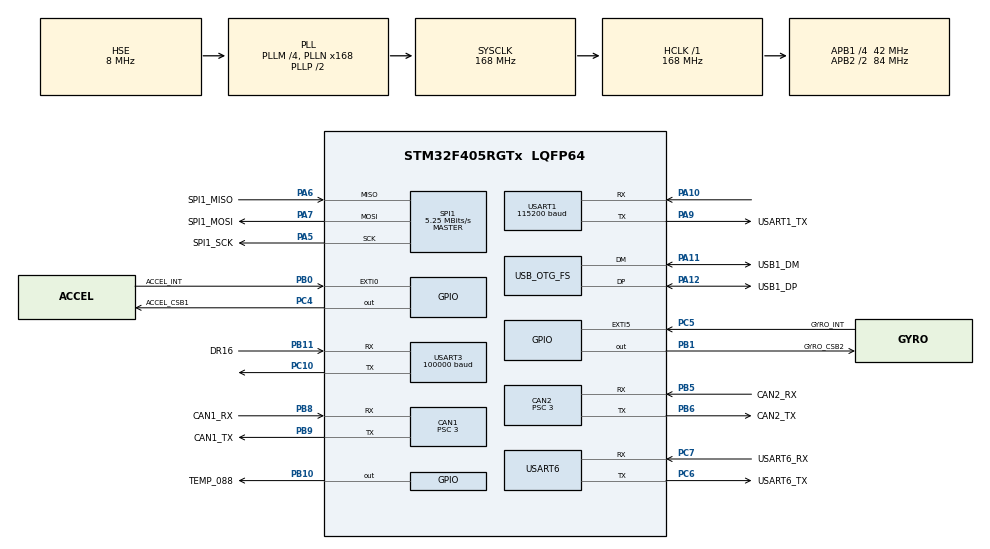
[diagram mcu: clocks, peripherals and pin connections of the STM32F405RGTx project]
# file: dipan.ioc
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CAN1.ABOM=ENABLE
CAN1.AWUM=ENABLE
CAN1.BS1=CAN_BS1_10TQ
CAN1.BS2=CAN_BS2_3TQ
CAN1.CalculateBaudRate=1000000
CAN1.CalculateTimeBit=1000
CAN1.CalculateTimeQuantum=71.42857142857143
CAN1.NART=ENABLE
CAN1.Prescaler=3
CAN2.ABOM=ENABLE
CAN2.AWUM=ENABLE
CAN2.BS1=CAN_BS1_10TQ
CAN2.BS2=CAN_BS2_3TQ
CAN2.CalculateBaudRate=1000000
CAN2.CalculateTimeBit=1000
CAN2.CalculateTimeQuantum=71.42857142857143
CAN2.NART=ENABLE
CAN2.Prescaler=3
Dma.Request0=SPI1_RX
Dma.Request1=SPI1_TX
Dma.Request2=USART1_RX
Dma.Request3=USART1_TX
Dma.Request4=USART6_RX
Dma.Request5=USART6_TX
Dma.Request6=USART3_RX
Dma.SPI1_RX.0.Direction=DMA_PERIPH_TO_MEMORY
Dma.SPI1_RX.0.FIFOMode=DMA_FIFOMODE_DISABLE
Dma.SPI1_RX.0.Instance=DMA2_Stream0
Dma.SPI1_RX.0.MemDataAlignment=DMA_MDATAALIGN_BYTE
Dma.SPI1_RX.0.MemInc=DMA_MINC_ENABLE
Dma.SPI1_RX.0.Mode=DMA_NORMAL
Dma.SPI1_RX.0.PeriphDataAlignment=DMA_PDATAALIGN_BYTE
Dma.SPI1_RX.0.PeriphInc=DMA_PINC_DISABLE
Dma.SPI1_RX.0.Priority=DMA_PRIORITY_LOW
Dma.SPI1_TX.1.Direction=DMA_MEMORY_TO_PERIPH
Dma.SPI1_TX.1.FIFOMode=DMA_FIFOMODE_DISABLE
Dma.SPI1_TX.1.Instance=DMA2_Stream3
Dma.SPI1_TX.1.MemDataAlignment=DMA_MDATAALIGN_BYTE
Dma.SPI1_TX.1.MemInc=DMA_MINC_ENABLE
Dma.SPI1_TX.1.Mode=DMA_NORMAL
Dma.SPI1_TX.1.PeriphDataAlignment=DMA_PDATAALIGN_BYTE
Dma.SPI1_TX.1.PeriphInc=DMA_PINC_DISABLE
Dma.SPI1_TX.1.Priority=DMA_PRIORITY_LOW
Dma.USART1_RX.2.Direction=DMA_PERIPH_TO_MEMORY
Dma.USART1_RX.2.FIFOMode=DMA_FIFOMODE_DISABLE
Dma.USART1_RX.2.Instance=DMA2_Stream2
Dma.USART1_RX.2.MemDataAlignment=DMA_MDATAALIGN_BYTE
Dma.USART1_RX.2.MemInc=DMA_MINC_ENABLE
Dma.USART1_RX.2.Mode=DMA_NORMAL
Dma.USART1_RX.2.PeriphDataAlignment=DMA_PDATAALIGN_BYTE
Dma.USART1_RX.2.PeriphInc=DMA_PINC_DISABLE
Dma.USART1_RX.2.Priority=DMA_PRIORITY_LOW
Dma.USART1_TX.3.Direction=DMA_MEMORY_TO_PERIPH
Dma.USART1_TX.3.FIFOMode=DMA_FIFOMODE_DISABLE
Dma.USART1_TX.3.Instance=DMA2_Stream7
Dma.USART1_TX.3.MemDataAlignment=DMA_MDATAALIGN_BYTE
Dma.USART1_TX.3.MemInc=DMA_MINC_ENABLE
Dma.USART1_TX.3.Mode=DMA_NORMAL
Dma.USART1_TX.3.PeriphDataAlignment=DMA_PDATAALIGN_BYTE
Dma.USART1_TX.3.PeriphInc=DMA_PINC_DISABLE
Dma.USART1_TX.3.Priority=DMA_PRIORITY_LOW
Dma.USART3_RX.6.Direction=DMA_PERIPH_TO_MEMORY
Dma.USART3_RX.6.FIFOMode=DMA_FIFOMODE_DISABLE
Dma.USART3_RX.6.Instance=DMA1_Stream1
Dma.USART3_RX.6.MemDataAlignment=DMA_MDATAALIGN_BYTE
Dma.USART3_RX.6.MemInc=DMA_MINC_ENABLE
Dma.USART3_RX.6.Mode=DMA_NORMAL
Dma.USART3_RX.6.PeriphDataAlignment=DMA_PDATAALIGN_BYTE
Dma.USART3_RX.6.PeriphInc=DMA_PINC_DISABLE
Dma.USART3_RX.6.Priority=DMA_PRIORITY_LOW
Dma.USART6_RX.4.Direction=DMA_PERIPH_TO_MEMORY
Dma.USART6_RX.4.FIFOMode=DMA_FIFOMODE_DISABLE
Dma.USART6_RX.4.Instance=DMA2_Stream1
Dma.USART6_RX.4.MemDataAlignment=DMA_MDATAALIGN_BYTE
Dma.USART6_RX.4.MemInc=DMA_MINC_ENABLE
Dma.USART6_RX.4.Mode=DMA_NORMAL
Dma.USART6_RX.4.PeriphDataAlignment=DMA_PDATAALIGN_BYTE
Dma.USART6_RX.4.PeriphInc=DMA_PINC_DISABLE
Dma.USART6_RX.4.Priority=DMA_PRIORITY_LOW
Dma.USART6_TX.5.Direction=DMA_MEMORY_TO_PERIPH
Dma.USART6_TX.5.FIFOMode=DMA_FIFOMODE_DISABLE
Dma.USART6_TX.5.Instance=DMA2_Stream6
Dma.USART6_TX.5.MemDataAlignment=DMA_MDATAALIGN_BYTE
Dma.USART6_TX.5.MemInc=DMA_MINC_ENABLE
Dma.USART6_TX.5.Mode=DMA_NORMAL
Dma.USART6_TX.5.PeriphDataAlignment=DMA_PDATAALIGN_BYTE
Dma.USART6_TX.5.PeriphInc=DMA_PINC_DISABLE
Dma.USART6_TX.5.Priority=DMA_PRIORITY_LOW
FREERTOS.Tasks01=defaultTask,24,128,StartDefaultTask,Default,NULL,Dynamic,NULL,NULL
FREERTOS.configTOTAL_HEAP_SIZE=30000
Mcu.Family=STM32F4
Mcu.Name=STM32F405RGTx
Mcu.Package=LQFP64
NVIC.CAN1_RX0_IRQn=true\:5\:0\:false\:false\:true\:true\:true\:true\:true
NVIC.CAN2_RX0_IRQn=true\:5\:0\:false\:false\:true\:true\:true\:true\:true
NVIC.DMA1_Stream1_IRQn=true\:5\:0\:false\:false\:true\:true\:false\:true\:true
NVIC.DMA2_Stream0_IRQn=true\:5\:0\:false\:false\:true\:true\:false\:true\:true
NVIC.DMA2_Stream1_IRQn=true\:5\:0\:false\:false\:true\:true\:false\:true\:true
NVIC.DMA2_Stream2_IRQn=true\:5\:0\:false\:false\:true\:true\:false\:true\:true
NVIC.DMA2_Stream3_IRQn=true\:5\:0\:false\:false\:true\:true\:false\:true\:true
NVIC.DMA2_Stream6_IRQn=true\:5\:0\:false\:false\:true\:true\:false\:true\:true
NVIC.DMA2_Stream7_IRQn=true\:5\:0\:false\:false\:true\:true\:false\:true\:true
NVIC.OTG_FS_IRQn=true\:5\:0\:false\:false\:true\:true\:false\:true\:true
NVIC.PriorityGroup=NVIC_PRIORITYGROUP_4
NVIC.TIM8_TRG_COM_TIM14_IRQn=true\:15\:0\:false\:false\:true\:false\:false\:true\:true
NVIC.TimeBase=TIM8_TRG_COM_TIM14_IRQn
NVIC.TimeBaseIP=TIM14
NVIC.USART1_IRQn=true\:5\:0\:false\:false\:true\:true\:false\:true\:true
NVIC.USART3_IRQn=true\:5\:0\:false\:false\:true\:true\:true\:true\:true
NVIC.USART6_IRQn=true\:5\:0\:false\:false\:true\:true\:false\:true\:true
PA10.Mode=Asynchronous
PA10.Signal=USART1_RX
PA11.GPIO_Label=USB1_DM
PA11.Mode=Device_Only
PA11.Signal=USB_OTG_FS_DM
PA12.GPIO_Label=USB1_DP
PA12.Mode=Device_Only
PA12.Signal=USB_OTG_FS_DP
PA13.Mode=Serial_Wire
PA13.Signal=SYS_JTMS-SWDIO
PA14.Mode=Serial_Wire
PA14.Signal=SYS_JTCK-SWCLK
PA5.GPIO_Label=SPI1_SCK
PA5.Mode=Full_Duplex_Master
PA5.Signal=SPI1_SCK
PA6.GPIO_Label=SPI1_MISO
PA6.Mode=Full_Duplex_Master
PA6.Signal=SPI1_MISO
PA7.GPIO_Label=SPI1_MOSI
PA7.Mode=Full_Duplex_Master
PA7.Signal=SPI1_MOSI
PA9.GPIO_Label=USART1_TX
PA9.Mode=Asynchronous
PA9.Signal=USART1_TX
PB0.GPIO_Label=ACCEL_INT
PB0.Signal=GPXTI0
PB1.GPIO_Label=GYRO_CSB2
PB1.PinState=GPIO_PIN_SET
PB1.Signal=GPIO_Output
PB10.GPIO_Label=TEMP_088
PB10.PinState=GPIO_PIN_SET
PB10.Signal=GPIO_Output
PB11.GPIO_Label=DR16
PB11.Mode=Asynchronous
PB11.Signal=USART3_RX
PB5.GPIO_Label=CAN2_RX
PB5.Mode=CAN_Activate
PB5.Signal=CAN2_RX
PB6.GPIO_Label=CAN2_TX
PB6.Mode=CAN_Activate
PB6.Signal=CAN2_TX
PB8.GPIO_Label=CAN1_RX
PB8.Mode=CAN_Activate
PB8.Signal=CAN1_RX
PB9.GPIO_Label=CAN1_TX
PB9.Mode=CAN_Activate
PB9.Signal=CAN1_TX
PC10.Mode=Asynchronous
PC10.Signal=USART3_TX
PC4.GPIO_Label=ACCEL_CSB1
PC4.PinState=GPIO_PIN_SET
PC4.Signal=GPIO_Output
PC5.GPIO_Label=GYRO_INT
PC5.Signal=GPXTI5
PC6.GPIO_Label=USART6_TX
PC6.Mode=Asynchronous
PC6.Signal=USART6_TX
PC7.GPIO_Label=USART6_RX
PC7.Mode=Asynchronous
PC7.Signal=USART6_RX
PH0-OSC_IN.Mode=HSE-External-Oscillator
PH0-OSC_IN.Signal=RCC_OSC_IN
PH1-OSC_OUT.Mode=HSE-External-Oscillator
PH1-OSC_OUT.Signal=RCC_OSC_OUT
ProjectManager.HeapSize=0x200
ProjectManager.StackSize=0x400
ProjectManager.TargetToolchain=CMake
RCC.48MHZClocksFreq_Value=48000000
RCC.AHBFreq_Value=168000000
RCC.APB1CLKDivider=RCC_HCLK_DIV4
RCC.APB1Freq_Value=42000000
RCC.APB1TimFreq_Value=84000000
RCC.APB2CLKDivider=RCC_HCLK_DIV2
RCC.APB2Freq_Value=84000000
RCC.APB2TimFreq_Value=168000000
RCC.CortexFreq_Value=168000000
RCC.HCLKFreq_Value=168000000
RCC.HSE_VALUE=8000000
RCC.HSI_VALUE=16000000
RCC.LSE_VALUE=32768
RCC.PLLM=4
RCC.PLLN=168
RCC.PLLQ=7
RCC.SYSCLKFreq_VALUE=168000000
RCC.SYSCLKSource=RCC_SYSCLKSOURCE_PLLCLK
RCC.VCOOutputFreq_Value=336000000
SPI1.BaudRatePrescaler=SPI_BAUDRATEPRESCALER_16
SPI1.CalculateBaudRate=5.25 MBits/s
SPI1.Direction=SPI_DIRECTION_2LINES
SPI1.Mode=SPI_MODE_MASTER
SPI1.VirtualType=VM_MASTER
TIM2.AutoReloadPreload=TIM_AUTORELOAD_PRELOAD_ENABLE
TIM2.Period=99999-1
TIM2.Prescaler=168-1
USART1.BaudRate=115200
USART1.Parity=PARITY_NONE
USART1.VirtualMode=VM_ASYNC
USART3.BaudRate=100000
USART3.Mode=MODE_RX
USART3.Parity=PARITY_EVEN
USART3.VirtualMode=VM_ASYNC
USART3.WordLength=WORDLENGTH_9B
USART6.VirtualMode=VM_ASYNC
USB_DEVICE.CLASS_NAME_FS=CDC
USB_DEVICE.VirtualMode-CDC_FS=Cdc
USB_DEVICE.VirtualModeFS=Cdc_FS
USB_OTG_FS.VirtualMode=Device_Only
VP_FREERTOS_VS_CMSIS_V2.Mode=CMSIS_V2
VP_SYS_VS_tim14.Mode=TIM14
VP_TIM2_VS_ClockSourceINT.Mode=Internal
VP_USB_DEVICE_VS_USB_DEVICE_CDC_FS.Mode=CDC_FS
board=custom

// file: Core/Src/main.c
/* USER CODE BEGIN Header */
/**
  ******************************************************************************
  * @file           : main.c
  * @brief          : Main program body
  ******************************************************************************
  * @attention
  *
  * Copyright (c) 2026 STMicroelectronics.
  * All rights reserved.
  *
  * This software is licensed under terms that can be found in the LICENSE file
  * in the root directory of this software component.
  * If no LICENSE file comes with this software, it is provided AS-IS.
  *
  ******************************************************************************
  */
/* USER CODE END Header */
#include "main.h"
#include "cmsis_os.h"
#include "can.h"
#include "dma.h"
#include "spi.h"
#include "tim.h"
#include "usart.h"
#include "usb_device.h"
#include "gpio.h"

/* USER CODE BEGIN Includes */
#include "Chassis.h"

/* USER CODE END Includes */

void SystemClock_Config(void);
void MX_FREERTOS_Init(void);

int main(void)
{

  /* MCU Configuration--------------------------------------------------------*/

  /* Reset of all peripherals, Initializes the Flash interface and the Systick. */
  HAL_Init();

  /* Configure the system clock */
  SystemClock_Config();

  /* Initialize all configured peripherals */
  MX_GPIO_Init();
  MX_DMA_Init();
  MX_CAN1_Init();
  MX_CAN2_Init();
  MX_SPI1_Init();
  MX_TIM2_Init();
  MX_USART1_UART_Init();
  MX_USART6_UART_Init();
  MX_USART3_UART_Init();

  /* Init scheduler */
  osKernelInitialize();  /* Call init function for freertos objects (in cmsis_os2.c) */
  MX_FREERTOS_Init();

  /* Start scheduler */
  osKernelStart();

  /* We should never get here as control is now taken by the scheduler */

  /* Infinite loop */
  while (1)
  {

  }
}

void SystemClock_Config(void)
{
  RCC_OscInitTypeDef RCC_OscInitStruct = {0};
  RCC_ClkInitTypeDef RCC_ClkInitStruct = {0};

  /** Configure the main internal regulator output voltage
  */
  __HAL_RCC_PWR_CLK_ENABLE();
  __HAL_PWR_VOLTAGESCALING_CONFIG(PWR_REGULATOR_VOLTAGE_SCALE1);

  /** Initializes the RCC Oscillators according to the specified parameters
  * in the RCC_OscInitTypeDef structure.
  */
  RCC_OscInitStruct.OscillatorType = RCC_OSCILLATORTYPE_HSE;
  RCC_OscInitStruct.HSEState = RCC_HSE_ON;
  RCC_OscInitStruct.PLL.PLLState = RCC_PLL_ON;
  RCC_OscInitStruct.PLL.PLLSource = RCC_PLLSOURCE_HSE;
  RCC_OscInitStruct.PLL.PLLM = 4;
  RCC_OscInitStruct.PLL.PLLN = 168;
  RCC_OscInitStruct.PLL.PLLP = RCC_PLLP_DIV2;
  RCC_OscInitStruct.PLL.PLLQ = 7;
  if (HAL_RCC_OscConfig(&RCC_OscInitStruct) != HAL_OK)
  {
    Error_Handler();
  }

  /** Initializes the CPU, AHB and APB buses clocks
  */
  RCC_ClkInitStruct.ClockType = RCC_CLOCKTYPE_HCLK|RCC_CLOCKTYPE_SYSCLK
                              |RCC_CLOCKTYPE_PCLK1|RCC_CLOCKTYPE_PCLK2;
  RCC_ClkInitStruct.SYSCLKSource = RCC_SYSCLKSOURCE_PLLCLK;
  RCC_ClkInitStruct.AHBCLKDivider = RCC_SYSCLK_DIV1;
  RCC_ClkInitStruct.APB1CLKDivider = RCC_HCLK_DIV4;
  RCC_ClkInitStruct.APB2CLKDivider = RCC_HCLK_DIV2;

  if (HAL_RCC_ClockConfig(&RCC_ClkInitStruct, FLASH_LATENCY_5) != HAL_OK)
  {
    Error_Handler();
  }
}

void HAL_TIM_PeriodElapsedCallback(TIM_HandleTypeDef *htim)
{
  if (htim->Instance == TIM14)
  {
    HAL_IncTick();
  }
  /* USER CODE BEGIN Callback 1 */
  if (htim->Instance == TIM2)
  {
    // 1ms节拍：刷新DR16的按键/拨杆边沿状态
    Chassis_Timer1msCallback();
  }
  /* USER CODE END Callback 1 */
}

void Error_Handler(void)
{
  __disable_irq();
  while (1)
  {
  }
}

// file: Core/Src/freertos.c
/* USER CODE BEGIN Header */
/**
  ******************************************************************************
  * File Name          : freertos.c
  * Description        : Code for freertos applications
  ******************************************************************************
  * @attention
  *
  * Copyright (c) 2026 STMicroelectronics.
  * All rights reserved.
  *
  * This software is licensed under terms that can be found in the LICENSE file
  * in the root directory of this software component.
  * If no LICENSE file comes with this software, it is provided AS-IS.
  *
  ******************************************************************************
  */
/* USER CODE END Header */

#include "FreeRTOS.h"
#include "task.h"
#include "main.h"
#include "cmsis_os.h"

/* USER CODE BEGIN Includes */
#include "MyTask.h"

/* USER CODE END Includes */

/* Definitions for defaultTask */
osThreadId_t defaultTaskHandle;
const osThreadAttr_t defaultTask_attributes = {
  .name = "defaultTask",
  .stack_size = 128 * 4,
  .priority = (osPriority_t) osPriorityNormal,
};

void StartDefaultTask(void *argument);

extern void MX_USB_DEVICE_Init(void);
void MX_FREERTOS_Init(void); /* (MISRA C 2004 rule 8.1) */

void MX_FREERTOS_Init(void) {

  /* Create the thread(s) */
  /* creation of defaultTask */
  defaultTaskHandle = osThreadNew(StartDefaultTask, NULL, &defaultTask_attributes);

}

void StartDefaultTask(void *argument)
{
  /* init code for USB_DEVICE */
  MX_USB_DEVICE_Init();
  /* USER CODE BEGIN StartDefaultTask */

  // 把底盘控制链挂到默认线程：
  // 初始化 -> 进入周期控制循环（函数内部自带while(1)）
  MyTask_Init();
  MyTask_Run();

  vTaskDelete(NULL); // 删除默认线程，剩下的控制链都在 MyTask_Run 创建的线程里了
  /* USER CODE END StartDefaultTask */
}
